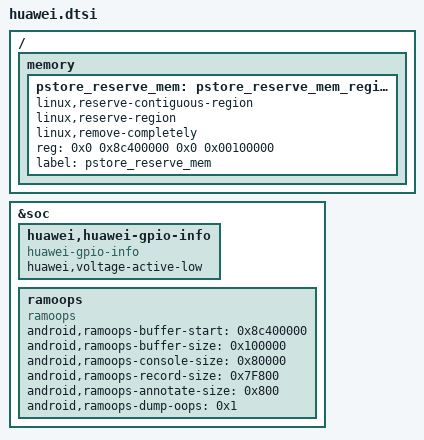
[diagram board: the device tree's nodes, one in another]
/*                                      Regulations
1.The "DTSxxx" just be allowed to  add at the begin and the tail.
2.The dtsi files which belong to a group need to be put together,and will be separated by remarks.
3.When we add one new boardid,it would be inherted from the similar one
 and modify the product name in the files of huawei-fac.dtsi huawei-wifi.dtsi huawei-audio.dtsi,
 and the other groups need to do some modify with DTSxxx.
*/
/*belong to the component group, according to the order of i2c lcd tp camera sensors compass tricolors vibrator begin*/
#include "huawei-lcd.dtsi"
#include "huawei-tp.dtsi"
#include "huawei-camera.dtsi"
#include "huawei-sensors.dtsi"
#include "huawei-vibrator.dtsi"
/*belong to the component group, according to the order of i2c lcd tp camera sensors compass tricolors vibrator end*/

/*belong to the wireless component group, according to the order of wifi bt fm audio begin*/
#include "huawei-fm.dtsi"
#include "huawei-bt.dtsi"
#include "huawei-audio.dtsi"
/*belong to the wireless component group, according to the order of wifi bt fm audio end*/

/ {
	memory {
		pstore_reserve_mem: pstore_reserve_mem_region@0 {
			linux,reserve-contiguous-region;
			linux,reserve-region;
			linux,remove-completely;
			reg = <0x0 0x8c400000 0x0 0x00100000>;
			label = "pstore_reserve_mem";
		};
	};
};

&soc {

	huawei,huawei-gpio-info {
		compatible = "huawei-gpio-info";
		huawei,voltage-active-low;
	};

	ramoops {
		compatible = "ramoops";
		status = "ok";

		android,ramoops-buffer-start = <0x8c400000>;
		android,ramoops-buffer-size = <0x100000>;
		android,ramoops-console-size = <0x80000>;
		android,ramoops-record-size = <0x7F800>;
		android,ramoops-annotate-size = <0x800>;
		android,ramoops-dump-oops = <0x1>;
	};
};
